# iosam3n register map
Registers are 32-bit, access not given, no defined reset value unless marked. A register's access mark holds for its fields unless they carry their own. Addresses are absolute; registers are grouped by the start of their names; [hi:lo] are bit positions; {n}, {i} and the like mark numbered series; 'fields as' and 'values as' point back to an identical list.

## TC1
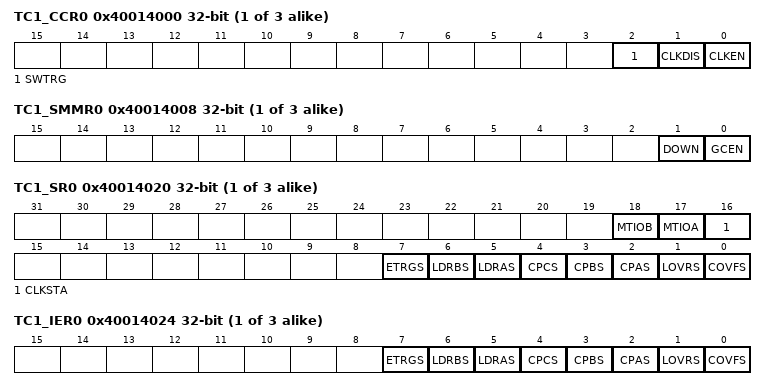
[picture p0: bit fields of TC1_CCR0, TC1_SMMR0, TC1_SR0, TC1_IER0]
{0x40014000+0x40*i} TC1_CCR{i} (i=0..2)
  [2] SWTRG, [1] CLKDIS, [0] CLKEN
{0x40014004+0x40*i} TC1_CMR{i} (i=0..2)
  [31:30] BSWTRG, [29:28] BEEVT, [27:26] BCPC, [25:24] BCPB, [23:22] ASWTRG, [21:20] AEEVT, [19:18] LDRB, [19:18] ACPC, [17:16] LDRA, [17:16] ACPA, [15] WAVE, [14] CPCTRG, [14:13] WAVSEL, [12] ENETRG, [10] ABETRG, [11:10] EEVT, [9:8] ETRGEDG, [9:8] EEVTEDG, [7] LDBDIS, [7] CPCDIS, [6] LDBSTOP, [6] CPCSTOP, [5:4] BURST, [3] CLKI, [2:0] TCCLKS
{0x40014008+0x40*i} TC1_SMMR{i} (i=0..2)
  [1] DOWN, [0] GCEN
{0x40014010+0x40*i} TC1_CV{i} (i=0..2)
  [15:0] CV
{0x40014014+0x40*i} TC1_RA{i} (i=0..2)
  [15:0] RA
{0x40014018+0x40*i} TC1_RB{i} (i=0..2)
  [15:0] RB
{0x4001401C+0x40*i} TC1_RC{i} (i=0..2)
  [15:0] RC
{0x40014020+0x40*i} TC1_SR{i} (i=0..2)
  [18] MTIOB, [17] MTIOA, [16] CLKSTA, [7] ETRGS, [6] LDRBS, [5] LDRAS, [4] CPCS, [3] CPBS, [2] CPAS, [1] LOVRS, [0] COVFS
{0x40014024+0x40*i} TC1_IER{i} (i=0..2)
  [7] ETRGS, [6] LDRBS, [5] LDRAS, [4] CPCS, [3] CPBS, [2] CPAS, [1] LOVRS, [0] COVFS
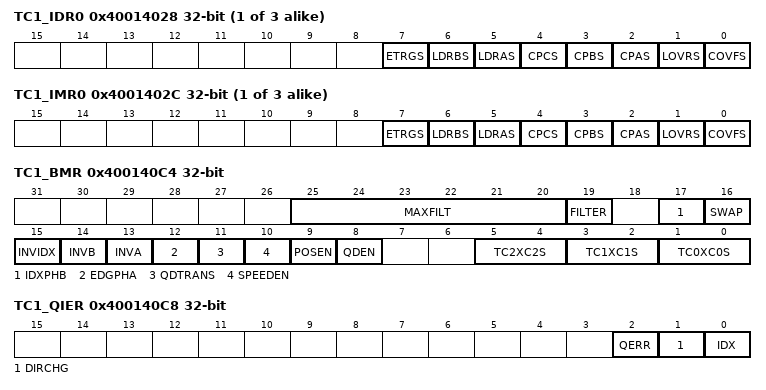
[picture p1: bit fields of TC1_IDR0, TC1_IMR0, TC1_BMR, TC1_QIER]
{0x40014028+0x40*i} TC1_IDR{i} (i=0..2)
  fields as TC1_IER0
{0x4001402C+0x40*i} TC1_IMR{i} (i=0..2)
  fields as TC1_IER0
0x400140C0 TC1_BCR
  [0] SYNC
0x400140C4 TC1_BMR
  [25:20] MAXFILT, [19] FILTER, [17] IDXPHB, [16] SWAP, [15] INVIDX, [14] INVB, [13] INVA, [12] EDGPHA, [11] QDTRANS, [10] SPEEDEN, [9] POSEN, [8] QDEN, [5:4] TC2XC2S, [3:2] TC1XC1S, [1:0] TC0XC0S
0x400140C8 TC1_QIER
  [2] QERR, [1] DIRCHG, [0] IDX
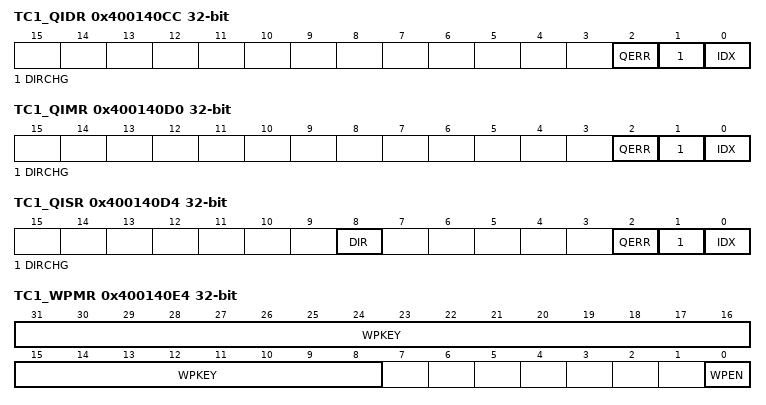
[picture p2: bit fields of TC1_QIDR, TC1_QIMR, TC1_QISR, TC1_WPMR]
0x400140CC TC1_QIDR
  [2] QERR, [1] DIRCHG, [0] IDX
0x400140D0 TC1_QIMR
  [2] QERR, [1] DIRCHG, [0] IDX
0x400140D4 TC1_QISR
  [8] DIR, [2] QERR, [1] DIRCHG, [0] IDX
0x400140E4 TC1_WPMR
  [31:8] WPKEY, [0] WPEN

## TWI0
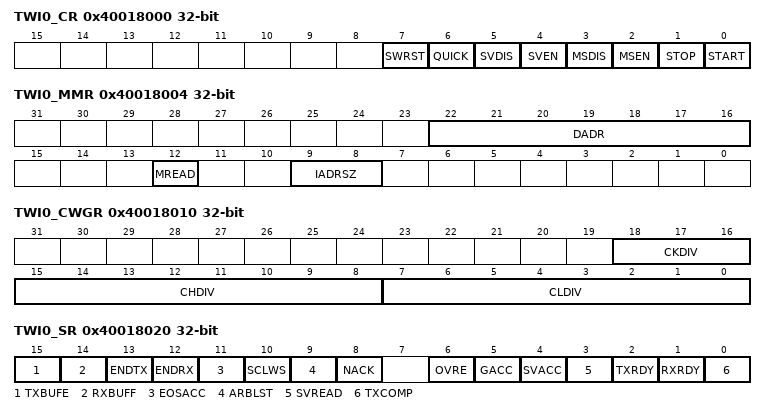
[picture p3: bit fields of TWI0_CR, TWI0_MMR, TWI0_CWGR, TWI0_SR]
0x40018000 TWI0_CR
  [7] SWRST, [6] QUICK, [5] SVDIS, [4] SVEN, [3] MSDIS, [2] MSEN, [1] STOP, [0] START
0x40018004 TWI0_MMR
  [22:16] DADR, [12] MREAD, [9:8] IADRSZ
0x40018008 TWI0_SMR
  [22:16] SADR
0x4001800C TWI0_IADR
  [23:0] IADR
0x40018010 TWI0_CWGR
  [18:16] CKDIV, [15:8] CHDIV, [7:0] CLDIV
0x40018020 TWI0_SR
  [15] TXBUFE, [14] RXBUFF, [13] ENDTX, [12] ENDRX, [11] EOSACC, [10] SCLWS, [9] ARBLST, [8] NACK, [6] OVRE, [5] GACC, [4] SVACC, [3] SVREAD, [2] TXRDY, [1] RXRDY, [0] TXCOMP
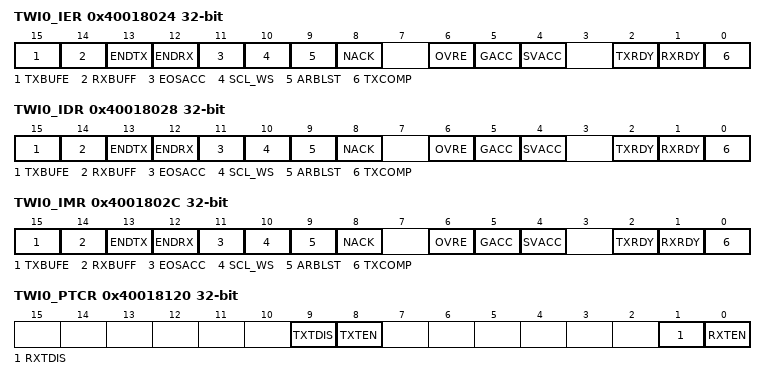
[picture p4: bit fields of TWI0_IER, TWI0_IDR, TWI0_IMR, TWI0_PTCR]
0x40018024 TWI0_IER
  [15] TXBUFE, [14] RXBUFF, [13] ENDTX, [12] ENDRX, [11] EOSACC, [10] SCL_WS, [9] ARBLST, [8] NACK, [6] OVRE, [5] GACC, [4] SVACC, [2] TXRDY, [1] RXRDY, [0] TXCOMP
0x40018028 TWI0_IDR
  fields as TWI0_IER
0x4001802C TWI0_IMR
  fields as TWI0_IER
0x40018030 TWI0_RHR
  [7:0] RXDATA
0x40018034 TWI0_THR
  [7:0] TXDATA
0x40018100 TWI0_RPR
  [31:0] RXPTR
0x40018104 TWI0_RCR
  [15:0] RXCTR
0x40018108 TWI0_TPR
  [31:0] TXPTR
0x4001810C TWI0_TCR
  [15:0] TXCTR
0x40018110 TWI0_RNPR
  [31:0] RXNPTR
0x40018114 TWI0_RNCR
  [15:0] RXNCTR
0x40018118 TWI0_TNPR
  [31:0] TXNPTR
0x4001811C TWI0_TNCR
  [15:0] TXNCTR
0x40018120 TWI0_PTCR
  [9] TXTDIS, [8] TXTEN, [1] RXTDIS, [0] RXTEN
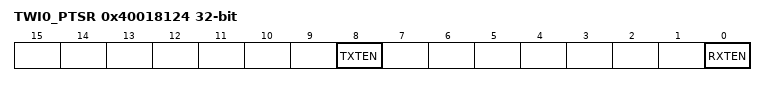
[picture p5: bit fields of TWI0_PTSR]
0x40018124 TWI0_PTSR
  [8] TXTEN, [0] RXTEN

## TWI1
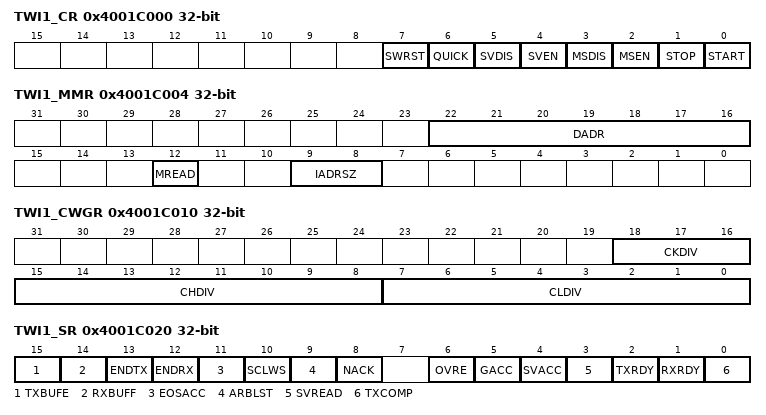
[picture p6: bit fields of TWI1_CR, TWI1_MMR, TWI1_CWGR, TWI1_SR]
0x4001C000 TWI1_CR
  [7] SWRST, [6] QUICK, [5] SVDIS, [4] SVEN, [3] MSDIS, [2] MSEN, [1] STOP, [0] START
0x4001C004 TWI1_MMR
  [22:16] DADR, [12] MREAD, [9:8] IADRSZ
0x4001C008 TWI1_SMR
  [22:16] SADR
0x4001C00C TWI1_IADR
  [23:0] IADR
0x4001C010 TWI1_CWGR
  [18:16] CKDIV, [15:8] CHDIV, [7:0] CLDIV
0x4001C020 TWI1_SR
  [15] TXBUFE, [14] RXBUFF, [13] ENDTX, [12] ENDRX, [11] EOSACC, [10] SCLWS, [9] ARBLST, [8] NACK, [6] OVRE, [5] GACC, [4] SVACC, [3] SVREAD, [2] TXRDY, [1] RXRDY, [0] TXCOMP
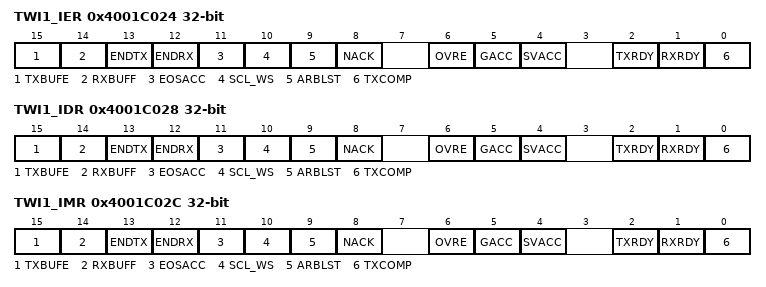
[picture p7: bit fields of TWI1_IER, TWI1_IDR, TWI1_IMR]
0x4001C024 TWI1_IER
  [15] TXBUFE, [14] RXBUFF, [13] ENDTX, [12] ENDRX, [11] EOSACC, [10] SCL_WS, [9] ARBLST, [8] NACK, [6] OVRE, [5] GACC, [4] SVACC, [2] TXRDY, [1] RXRDY, [0] TXCOMP
0x4001C028 TWI1_IDR
  fields as TWI1_IER
0x4001C02C TWI1_IMR
  fields as TWI1_IER
0x4001C030 TWI1_RHR
  [7:0] RXDATA
0x4001C034 TWI1_THR
  [7:0] TXDATA
